VERSION ""

NS_ :

BS_:

BU_: aiBoxFrontSteering Dashboard ciBoxRear aiBoxRear Datalogger ciBoxFront aiBoxFrontPedals MainECU
VAL_TABLE_ IgnitionStatus 3 "Non initialized" 2 "Ignition" 1 "Key present" 0 "Key not present" ;
VAL_TABLE_ TSAL_Status 3 "Undefined" 2 "Faulted" 1 "Active" 0 "Inactive" ;
VAL_TABLE_ Status 3 "Undefined" 2 "Reserved" 1 "Faulted" 0 "Ok" ;
VAL_TABLE_ PowerMode 255 "Undefined" 4 "Stopped" 3 "Faulted" 2 "RTD" 1 "Idle" 0 "StartUp" ;
VAL_TABLE_ NetworkMode 129 "Reset Node" 2 "Stop Node" 1 "Start Node" ;

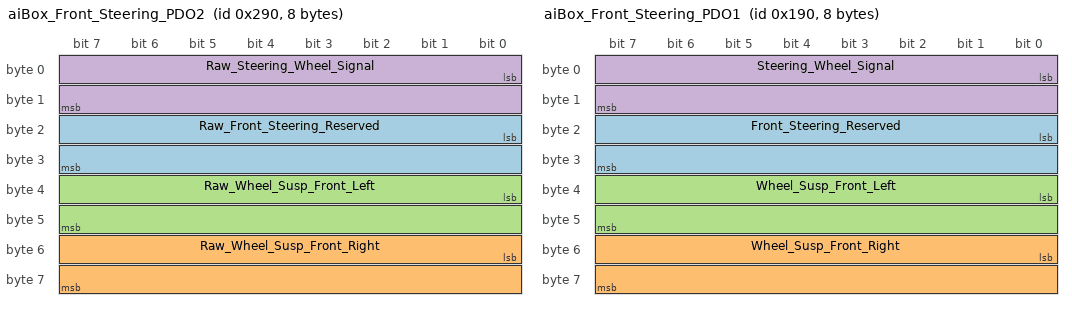
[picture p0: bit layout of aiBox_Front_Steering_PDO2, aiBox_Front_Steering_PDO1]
BO_ 656 aiBox_Front_Steering_PDO2: 8 aiBoxFrontSteering
 SG_ Raw_Front_Steering_Reserved : 16|16@1+ (1,0) [0|0] "" Vector__XXX
 SG_ Raw_Wheel_Susp_Front_Right : 48|16@1- (1,0) [0|0] ""  MainECU
 SG_ Raw_Wheel_Susp_Front_Left : 32|16@1- (1,0) [0|0] ""  MainECU
 SG_ Raw_Steering_Wheel_Signal : 0|16@1- (1,0) [0|0] ""  MainECU

BO_ 400 aiBox_Front_Steering_PDO1: 8 aiBoxFrontSteering
 SG_ Front_Steering_Reserved : 16|16@1+ (0.0036622,-120) [-120|120] "°" Vector__XXX
 SG_ Wheel_Susp_Front_Right : 48|16@1+ (1,0) [0|0] ""  MainECU
 SG_ Wheel_Susp_Front_Left : 32|16@1+ (1,0) [0|0] ""  MainECU
 SG_ Steering_Wheel_Signal : 0|16@1+ (0.0036622,-120) [-120|120] "°"  MainECU

BO_ 1808 aiBox_Front_Steering_Heartbeat: 8 aiBoxFrontSteering
 SG_ aiBox_Front_Steering_Hb_Status : 7|8@0+ (1,0) [0|0] ""  MainECU

BO_ 144 aiBox_Front_Steering_Emergency: 8 aiBoxFrontSteering
 SG_ ErrorField_ai_Front_Steering : 31|40@0+ (1,0) [0|0] ""  MainECU
 SG_ ErrorCode_aiBox_Front_Steering : 7|16@0+ (1,0) [0|0] ""  MainECU

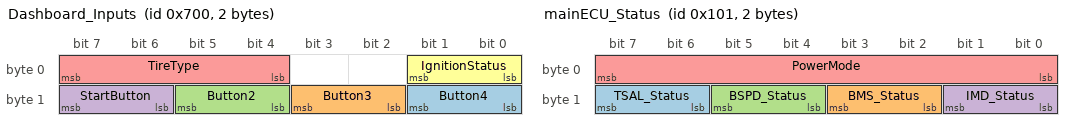
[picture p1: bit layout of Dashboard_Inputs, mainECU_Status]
BO_ 1792 Dashboard_Inputs: 2 Vector__XXX
 SG_ Button4 : 9|2@0+ (1,0) [0|0] ""  MainECU
 SG_ Button3 : 11|2@0+ (1,0) [0|0] ""  MainECU
 SG_ Button2 : 13|2@0+ (1,0) [0|0] ""  MainECU
 SG_ StartButton : 15|2@0+ (1,0) [0|0] ""  MainECU
 SG_ TireType : 7|4@0+ (1,0) [0|0] ""  MainECU
 SG_ IgnitionStatus : 1|2@0+ (1,0) [0|0] ""  MainECU

BO_ 257 mainECU_Status: 2 MainECU
 SG_ TSAL_Status : 15|2@0- (1,0) [0|0] "" Vector__XXX
 SG_ BMS_Status : 11|2@0- (1,0) [0|0] "" Vector__XXX
 SG_ BSPD_Status : 13|2@0- (1,0) [0|0] "" Vector__XXX
 SG_ IMD_Status : 9|2@0- (1,0) [0|0] "" Vector__XXX
 SG_ PowerMode : 7|8@0+ (1,0) [0|0] "" Vector__XXX

BO_ 1800 ciBox_Rear_Heartbeat: 8 ciBoxRear
 SG_ ciBox_Rear_HeartbeatStatus : 0|8@1- (1,0) [0|0] ""  MainECU

BO_ 136 ciBox_Rear_Emergency: 8 ciBoxFront
 SG_ Emergency_ErrorCode_ciBox_rear : 47|8@0+ (1,0) [0|0] ""  MainECU
 SG_ ErrorField_ci_Rear_Emergency : 7|40@0+ (1,0) [0|0] ""  MainECU

BO_ 1794 ciBox_Front_Heartbeat: 8 ciBoxFront
 SG_ ciBox_Front_HeartbeatStatus : 0|8@1- (1,0) [0|0] ""  MainECU

BO_ 130 ciBox_Front_Emergency: 8 ciBoxFront
 SG_ Emergency_ErrorCode_ciBox_front : 47|8@0+ (1,0) [0|0] ""  MainECU
 SG_ ErrorField_ci_Front_Emergency : 7|40@0+ (1,0) [0|0] ""  MainECU

BO_ 1796 aiBox_Rear_Heartbeat: 8 aiBoxRear
 SG_ aiBox_Rear_HeartbeatStatus : 0|8@1- (1,0) [0|0] ""  MainECU

BO_ 644 aiBox_Rear_PDO2: 8 aiBoxRear
 SG_ Raw_Wheel_Susp_Rear_Right : 16|16@1+ (1,0) [0|0] ""  MainECU
 SG_ Raw_Wheel_Susp_Rear_Left : 0|16@1+ (1,0) [0|0] ""  MainECU

BO_ 132 aiBox_Rear_Emergency: 8 aiBoxRear
 SG_ ErrorField_ai_Rear_Emergency : 23|40@0+ (1,0) [0|0] ""  MainECU
 SG_ Emergency_ErrorCode_aiBox_rear : 7|16@0+ (1,0) [0|0] ""  MainECU

BO_ 388 aiBox_Rear_PDO1: 8 aiBoxRear
 SG_ Wheel_Susp_Rear_Left : 0|16@1+ (1,0) [0|0] ""  MainECU
 SG_ Wheel_Susp_Rear_Right : 16|16@1+ (1,0) [0|0] ""  MainECU

BO_ 392 ciBox_Rear_PDO1: 8 ciBoxRear
 SG_ Wheel_Speed_Rear_Right : 16|16@1+ (1,0) [0|0] ""  MainECU
 SG_ Wheel_Speed_Rear_Left : 0|16@1+ (1,0) [0|0] ""  MainECU

BO_ 386 ciBox_Front_PDO1: 8 ciBoxFront
 SG_ Wheel_Speed_Front_Right : 16|16@1+ (1,0) [0|0] ""  MainECU
 SG_ Wheel_Speed_Front_Left : 0|16@1+ (1,0) [0|0] ""  MainECU

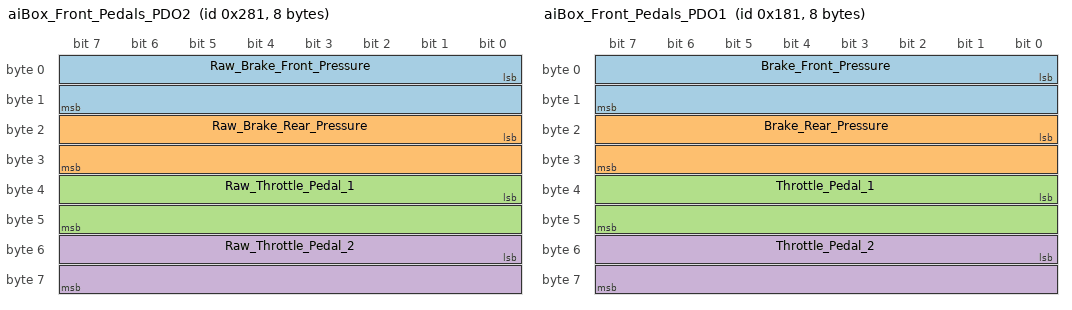
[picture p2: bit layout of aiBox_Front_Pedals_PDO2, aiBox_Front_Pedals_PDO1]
BO_ 641 aiBox_Front_Pedals_PDO2: 8 aiBoxFrontPedals
 SG_ Raw_Brake_Front_Pressure : 0|16@1- (1,0) [0|0] ""  MainECU
 SG_ Raw_Brake_Rear_Pressure : 16|16@1- (1,0) [0|0] ""  MainECU
 SG_ Raw_Throttle_Pedal_1 : 32|16@1- (1,0) [0|0] ""  MainECU
 SG_ Raw_Throttle_Pedal_2 : 48|16@1- (1,0) [0|0] ""  MainECU

BO_ 0 NM: 2 MainECU
 SG_ Node : 15|8@0+ (1,0) [0|0] ""  aiBoxFrontSteering,MainECU,aiBoxRear,ciBoxRear,ciBoxFront,aiBoxFrontPedals
 SG_ Mode : 7|8@0+ (1,0) [0|0] ""  aiBoxFrontSteering,MainECU,aiBoxRear,ciBoxRear,ciBoxFront,aiBoxFrontPedals

BO_ 1793 aiBox_Front_Pedals_Heartbeat: 8 aiBoxFrontPedals
 SG_ aiBox_Front_Pedals_Hb_Status : 7|8@0+ (1,0) [0|0] ""  MainECU

BO_ 385 aiBox_Front_Pedals_PDO1: 8 aiBoxFrontPedals
 SG_ Brake_Front_Pressure : 0|16@1- (0.0015259,0) [0|100] "%"  MainECU
 SG_ Brake_Rear_Pressure : 16|16@1- (0.0015259,0) [0|100] "%"  MainECU
 SG_ Throttle_Pedal_1 : 32|16@1- (0.0015259,0) [0|100] "%"  MainECU
 SG_ Throttle_Pedal_2 : 48|16@1- (0.0015259,0) [0|100] "%"  MainECU

BO_ 129 aiBox_Front_Pedals_Emergency: 8 aiBoxFrontPedals
 SG_ ErrorField_ai_Front_Pedals : 31|40@0+ (1,0) [0|0] ""  MainECU
 SG_ ErrorCode_aiBox_Front_Pedals : 7|16@0+ (1,0) [0|0] ""  MainECU

BA_DEF_ SG_  "GenSigEnvVarType" ENUM  "int","float","undef";
BA_DEF_ SG_  "GenSigStartValue" FLOAT 0 100000000000;
BA_DEF_ SG_  "GenSigSendType" ENUM  "Cyclic","OnWrite","OnWriteWithRepetition","OnChange","OnChangeWithRepetition","IfActive","IfActiveWithRepetition";
BA_DEF_ BO_  "GenMsgDelayTime" INT 1 1000;
BA_DEF_ BO_  "GenMsgCycleTime" INT 2 50000;
BA_DEF_ BO_  "GenMsgSendType" ENUM  "Cyclic","not_used","not_used","not_used","not_used","Cyclic","not_used","IfActive";
BA_DEF_ BO_  "GenMsgCycleTimeFast" INT 2 100000;
BA_DEF_ BO_  "GenMsgILSupport" ENUM  "No","Yes";
BA_DEF_ BU_  "TpNodeBaseAddress" HEX 0 33554431;
BA_DEF_ BU_  "TpUseFC" INT 0 1;
BA_DEF_ BU_  "TpCanBus" INT 1 2;
BA_DEF_ BU_  "TpRxMask" HEX 0 65535;
BA_DEF_ BU_  "TpRxIdentifier" HEX 0 536870911;
BA_DEF_ BU_  "TpTxIdentifier" HEX 0 536870911;
BA_DEF_ BU_  "NodeLayerModules" STRING ;
BA_DEF_ BU_  "ILUsed" ENUM  "Yes","No";
BA_DEF_ BU_  "TpAddressingMode" INT 0 3;
BA_DEF_  "NmBaseAddress" HEX 1024 1055;
BA_DEF_  "GenEnvVarPrefix" STRING ;
BA_DEF_  "GenEnvVarEndingSnd" STRING ;
BA_DEF_  "GenEnvVarEndingDsp" STRING ;
BA_DEF_  "BusType" STRING ;
BA_DEF_DEF_  "GenSigEnvVarType" "undef";
BA_DEF_DEF_  "GenSigStartValue" 0;
BA_DEF_DEF_  "GenSigSendType" "Cyclic";
BA_DEF_DEF_  "GenMsgDelayTime" 1;
BA_DEF_DEF_  "GenMsgCycleTime" 2;
BA_DEF_DEF_  "GenMsgSendType" "not_used";
BA_DEF_DEF_  "GenMsgCycleTimeFast" 100;
BA_DEF_DEF_  "GenMsgILSupport" "Yes";
BA_DEF_DEF_  "TpNodeBaseAddress" 1536;
BA_DEF_DEF_  "TpUseFC" 1;
BA_DEF_DEF_  "TpCanBus" 1;
BA_DEF_DEF_  "TpRxMask" 255;
BA_DEF_DEF_  "TpRxIdentifier" 1;
BA_DEF_DEF_  "TpTxIdentifier" 1;
BA_DEF_DEF_  "NodeLayerModules" "oseknm01.dll";
BA_DEF_DEF_  "ILUsed" "Yes";
BA_DEF_DEF_  "TpAddressingMode" 1;
BA_DEF_DEF_  "NmBaseAddress" 1024;
BA_DEF_DEF_  "GenEnvVarPrefix" "Env";
BA_DEF_DEF_  "GenEnvVarEndingSnd" "_";
BA_DEF_DEF_  "GenEnvVarEndingDsp" "Dsp_";
BA_DEF_DEF_  "BusType" "CAN";
BA_ "GenMsgCycleTime" BO_ 656 20;
BA_ "GenMsgSendType" BO_ 656 0;
BA_ "GenMsgCycleTime" BO_ 400 20;
BA_ "GenMsgSendType" BO_ 400 0;
BA_ "GenMsgCycleTimeFast" BO_ 400 20;
BA_ "GenMsgCycleTime" BO_ 1808 1000;
BA_ "GenMsgSendType" BO_ 641 0;
BA_ "GenMsgCycleTime" BO_ 641 20;
BA_ "GenMsgCycleTime" BO_ 1793 1000;
BA_ "GenMsgCycleTime" BO_ 385 20;
BA_ "GenMsgSendType" BO_ 385 0;
BA_ "GenMsgCycleTimeFast" BO_ 385 20;
BA_ "GenSigStartValue" SG_ 400 Front_Steering_Reserved 32767.1891212932;
BA_ "GenSigStartValue" SG_ 400 Steering_Wheel_Signal 32767.1891212932;
BA_ "GenSigStartValue" SG_ 257 PowerMode 255;
VAL_ 1808 aiBox_Front_Steering_Hb_Status 127 "Pre-operational" 5 "Operational" 4 "Stopped" 1 "Off bus" 0 "Boot-up" ;
VAL_ 1792 IgnitionStatus 3 "Non initialized" 2 "Ignition" 1 "Key present" 0 "Key not present" ;
VAL_ 257 TSAL_Status 3 "Undefined" 2 "Faulted" 1 "Active" 0 "Inactive" ;
VAL_ 257 BMS_Status 3 "Undefined" 2 "Reserved" 1 "Faulted" 0 "Ok" ;
VAL_ 257 BSPD_Status 3 "Undefined" 2 "Reserved" 1 "Faulted" 0 "Ok" ;
VAL_ 257 IMD_Status 3 "Undefined" 2 "Reserved" 1 "Faulted" 0 "Ok" ;
VAL_ 257 PowerMode 255 "Undefined" 4 "Stopped" 3 "Faulted" 2 "RTD" 1 "Idle" 0 "StartUp" ;
VAL_ 1800 ciBox_Rear_HeartbeatStatus 127 "Pre-operational" 5 "Operational" 4 "Stopped" 1 "Off bus" 0 "Boot-up" ;
VAL_ 1794 ciBox_Front_HeartbeatStatus 127 "Pre-operational" 5 "Operational" 4 "Stopped" 1 "Off bus" 0 "Boot-up" ;
VAL_ 1796 aiBox_Rear_HeartbeatStatus 127 "Pre-operational" 5 "Operational" 4 "Stopped" 1 "Off bus" 0 "Boot-up" ;
VAL_ 0 Mode 129 "Reset Node" 2 "Stop Node" 1 "Start Node" ;
VAL_ 1793 aiBox_Front_Pedals_Hb_Status 127 "Pre-operational" 5 "Operational" 4 "Stopped" 1 "Off bus" 0 "Boot-up" ;
